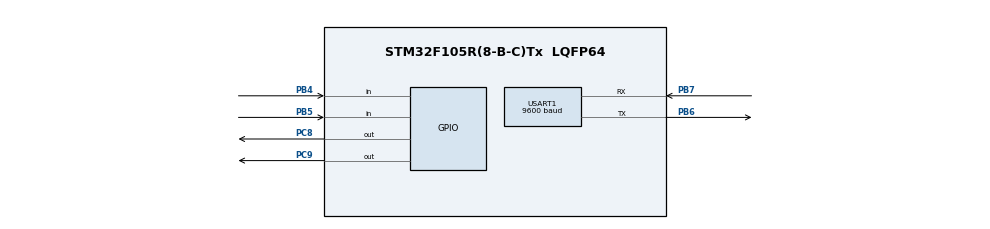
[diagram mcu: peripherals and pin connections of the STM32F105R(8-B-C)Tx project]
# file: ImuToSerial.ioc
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Mcu.Family=STM32F1
Mcu.Name=STM32F105R(8-B-C)Tx
Mcu.Package=LQFP64
NVIC.PriorityGroup=NVIC_PRIORITYGROUP_4
PA13.Mode=Serial_Wire
PA13.Signal=SYS_JTMS-SWDIO
PA14.Mode=Serial_Wire
PA14.Signal=SYS_JTCK-SWCLK
PB10.Signal=I2C2_SCL
PB11.Signal=I2C2_SDA
PB4.Signal=GPIO_Input
PB5.Signal=GPIO_Input
PB6.Mode=Asynchronous
PB6.Signal=USART1_TX
PB7.Mode=Asynchronous
PB7.Signal=USART1_RX
PC8.Signal=GPIO_Output
PC9.Signal=GPIO_Output
ProjectManager.HeapSize=0x200
ProjectManager.StackSize=0x400
ProjectManager.TargetToolchain=STM32CubeIDE
RCC.USBFreq_Value=10666666.666666666
USART1.BaudRate=9600
USART1.VirtualMode=VM_ASYNC
board=custom

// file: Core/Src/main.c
/* USER CODE BEGIN Header */
/**
  ******************************************************************************
  * @file           : main.c
  * @brief          : Main program body
  ******************************************************************************
  * @attention
  *
  * <h2><center>&copy; Copyright (c) 2021 STMicroelectronics.
  * All rights reserved.</center></h2>
  *
  * This software component is licensed by ST under BSD 3-Clause license,
  * the "License"; You may not use this file except in compliance with the
  * License. You may obtain a copy of the License at:
  *                        opensource.org/licenses/BSD-3-Clause
  *
  ******************************************************************************
  */
/* USER CODE END Header */
#include "main.h"
#include <stdio.h>

/* USER CODE BEGIN PD */
#define LED_GREEN (1U<<8)
#define LED_RED (1U<<9)

/* USER CODE END PD */

UART_HandleTypeDef huart1;
uint8_t MSG[35] = {'\0'};

void SystemClock_Config(void);
static void MX_GPIO_Init(void);
static void MX_USART1_UART_Init(void);

int main(void)
{

  /* MCU Configuration--------------------------------------------------------*/

  /* Reset of all peripherals, Initializes the Flash interface and the Systick. */
  HAL_Init();

  /* Configure the system clock */
  SystemClock_Config();

  /* Initialize all configured peripherals */
  MX_GPIO_Init();
  MX_USART1_UART_Init();

  /* Infinite loop */
  while (1)
  {
	  GPIOC->ODR |=LED_GREEN;
	  GPIOC->ODR |=LED_RED;
	  sprintf(MSG, "Harisree Ganapathaye Nama: \r\n");
	  HAL_UART_Transmit(&huart1, MSG, sizeof(MSG), 100);
	  HAL_Delay(1000);
	  GPIOC->ODR &=~LED_GREEN;
	  GPIOC->ODR &=~LED_RED;
	  HAL_Delay(1000);

  }
}

void SystemClock_Config(void)
{
  RCC_OscInitTypeDef RCC_OscInitStruct = {0};
  RCC_ClkInitTypeDef RCC_ClkInitStruct = {0};

  /** Initializes the RCC Oscillators according to the specified parameters
  * in the RCC_OscInitTypeDef structure.
  */
  RCC_OscInitStruct.OscillatorType = RCC_OSCILLATORTYPE_HSI;
  RCC_OscInitStruct.HSIState = RCC_HSI_ON;
  RCC_OscInitStruct.HSICalibrationValue = RCC_HSICALIBRATION_DEFAULT;
  RCC_OscInitStruct.PLL.PLLState = RCC_PLL_NONE;
  RCC_OscInitStruct.PLL2.PLL2State = RCC_PLL_NONE;
  if (HAL_RCC_OscConfig(&RCC_OscInitStruct) != HAL_OK)
  {
    Error_Handler();
  }
  /** Initializes the CPU, AHB and APB buses clocks
  */
  RCC_ClkInitStruct.ClockType = RCC_CLOCKTYPE_HCLK|RCC_CLOCKTYPE_SYSCLK
                              |RCC_CLOCKTYPE_PCLK1|RCC_CLOCKTYPE_PCLK2;
  RCC_ClkInitStruct.SYSCLKSource = RCC_SYSCLKSOURCE_HSI;
  RCC_ClkInitStruct.AHBCLKDivider = RCC_SYSCLK_DIV1;
  RCC_ClkInitStruct.APB1CLKDivider = RCC_HCLK_DIV1;
  RCC_ClkInitStruct.APB2CLKDivider = RCC_HCLK_DIV1;

  if (HAL_RCC_ClockConfig(&RCC_ClkInitStruct, FLASH_LATENCY_0) != HAL_OK)
  {
    Error_Handler();
  }
  /** Configure the Systick interrupt time
  */
  __HAL_RCC_PLLI2S_ENABLE();
}

static void MX_USART1_UART_Init(void)
{

  huart1.Instance = USART1;
  huart1.Init.BaudRate = 9600;
  huart1.Init.WordLength = UART_WORDLENGTH_8B;
  huart1.Init.StopBits = UART_STOPBITS_1;
  huart1.Init.Parity = UART_PARITY_NONE;
  huart1.Init.Mode = UART_MODE_TX_RX;
  huart1.Init.HwFlowCtl = UART_HWCONTROL_NONE;
  huart1.Init.OverSampling = UART_OVERSAMPLING_16;
  if (HAL_UART_Init(&huart1) != HAL_OK)
  {
    Error_Handler();
  }

}

static void MX_GPIO_Init(void)
{
  GPIO_InitTypeDef GPIO_InitStruct = {0};

  /* GPIO Ports Clock Enable */
  __HAL_RCC_GPIOB_CLK_ENABLE();
  __HAL_RCC_GPIOC_CLK_ENABLE();
  __HAL_RCC_GPIOA_CLK_ENABLE();

  /*Configure GPIO pin Output Level */
  HAL_GPIO_WritePin(GPIOC, GPIO_PIN_8|GPIO_PIN_9, GPIO_PIN_RESET);

  /*Configure GPIO pins : PB10 PB11 */
  GPIO_InitStruct.Pin = GPIO_PIN_10|GPIO_PIN_11;
  GPIO_InitStruct.Mode = GPIO_MODE_AF_OD;
  GPIO_InitStruct.Speed = GPIO_SPEED_FREQ_HIGH;
  HAL_GPIO_Init(GPIOB, &GPIO_InitStruct);

  /*Configure GPIO pins : PC8 PC9 */
  GPIO_InitStruct.Pin = GPIO_PIN_8|GPIO_PIN_9;
  GPIO_InitStruct.Mode = GPIO_MODE_OUTPUT_PP;
  GPIO_InitStruct.Pull = GPIO_NOPULL;
  GPIO_InitStruct.Speed = GPIO_SPEED_FREQ_LOW;
  HAL_GPIO_Init(GPIOC, &GPIO_InitStruct);

  /*Configure GPIO pins : PB4 PB5 */
  GPIO_InitStruct.Pin = GPIO_PIN_4|GPIO_PIN_5;
  GPIO_InitStruct.Mode = GPIO_MODE_INPUT;
  GPIO_InitStruct.Pull = GPIO_NOPULL;
  HAL_GPIO_Init(GPIOB, &GPIO_InitStruct);

}

void Error_Handler(void)
{
  __disable_irq();
  while (1)
  {
  }
}

/************************ (C) COPYRIGHT STMicroelectronics *****END OF FILE****/
